# CC1312PSIP register map
File version: 1.0
CPU: CM4 1.0, other endian, MPU, FPU, 3 interrupt priority bits
Registers are 32-bit, read-write, reset 0x0 unless marked. A register's access mark holds for its fields unless they carry their own. Offsets are from the block's base; [hi:lo] are bit positions; {n}, {i} and the like mark numbered series.

## CCFG — Customer configuration area (CCFG)
Base 0x50003000
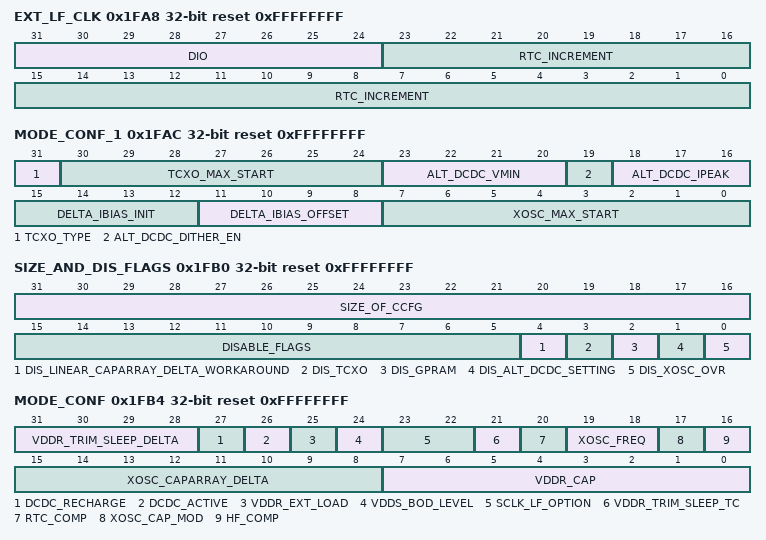
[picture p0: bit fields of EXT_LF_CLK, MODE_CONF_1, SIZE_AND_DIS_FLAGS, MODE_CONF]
0x1FA8 EXT_LF_CLK reset 0xFFFFFFFF — Extern LF clock configuration
  [31:24] DIO — [31:24] Unsigned integer, selecting the DIO to supply external 32 kHz clock as SCLK_LF when MODE_CONF.SCLK_LF_OPTION is set to EXTERNAL. The selected DIO will be marked as reserved by the pin driver (TI-RTOS environment) and hence not selectable for other usage.
  [23:0] RTC_INCREMENT — [23:0] Unsigned integer, defining the input frequency of the external clock and is written to AON_RTC:SUBSECINC.VALUEINC. Defined as follows: EXT_LF_CLK.RTC_INCREMENT = 2^38/InputClockFrequency in Hertz (e.g.: RTC_INCREMENT=0x800000 for InputClockFrequency=32768 Hz)
0x1FAC MODE_CONF_1 reset 0xFFFFFFFF — Mode Configuration 1
  [31] TCXO_TYPE — [31:31] Selects the TCXO type. 0: CMOS type. Internal common-mode bias will not be enabled. 1: Clipped-sine type. Internal common-mode bias will be enabled when TCXO is used. Bit field value is only valid if MODE_CONF.XOSC_FREQ=0.
  [30:24] TCXO_MAX_START — [30:24] Maximum TCXO startup time in units of 100us. Bit field value is only valid if MODE_CONF.XOSC_FREQ=0.
  [23:20] ALT_DCDC_VMIN — [23:20] Minimum voltage for when DC/DC should be used if alternate DC/DC setting is enabled (SIZE_AND_DIS_FLAGS.DIS_ALT_DCDC_SETTING=0). Voltage = (28 + ALT_DCDC_VMIN) / 16. 0: 1.75V 1: 1.8125V ... 14: 2.625V 15: 2.6875V NOTE! The DriverLib function SysCtrl_DCDC_VoltageConditionalControl() must be called regularly to apply this field (handled automatically if using TI RTOS!).
  [19] ALT_DCDC_DITHER_EN — [19:19] Enable DC/DC dithering if alternate DC/DC setting is enabled (SIZE_AND_DIS_FLAGS.DIS_ALT_DCDC_SETTING=0). 0: Dither disable 1: Dither enable
  [18:16] ALT_DCDC_IPEAK — [18:16] Inductor peak current if alternate DC/DC setting is enabled (SIZE_AND_DIS_FLAGS.DIS_ALT_DCDC_SETTING=0). Assuming 10uH external inductor! 0: 46mA (min) ... 4: 70mA ... 7: 87mA (max)
  [15:12] DELTA_IBIAS_INIT — [15:12] Signed delta value for IBIAS_INIT. Delta value only applies if SIZE_AND_DIS_FLAGS.DIS_XOSC_OVR=0. See FCFG1:AMPCOMP_CTRL1.IBIAS_INIT
  [11:8] DELTA_IBIAS_OFFSET — [11:8] Signed delta value for IBIAS_OFFSET. Delta value only applies if SIZE_AND_DIS_FLAGS.DIS_XOSC_OVR=0. See FCFG1:AMPCOMP_CTRL1.IBIAS_OFFSET
  [7:0] XOSC_MAX_START — [7:0] Unsigned value of maximum XOSC startup time (worst case) in units of 100us. Value only applies if SIZE_AND_DIS_FLAGS.DIS_XOSC_OVR=0.
0x1FB0 SIZE_AND_DIS_FLAGS reset 0xFFFFFFFF — CCFG Size and Disable Flags
  [31:16] SIZE_OF_CCFG — [31:16] Total size of CCFG in bytes.
  [15:5] DISABLE_FLAGS — [15:5] Reserved for future use. Software should not rely on the value of a reserved. Writing any other value than the reset/default value may result in undefined behavior.
  [4] DIS_LINEAR_CAPARRAY_DELTA_WORKAROUND — [4:4] The default CAPARRAY setting is good as long as no CAPARRAY_DELTA adjustment is added but the CAPARRAY setting will give an un-linear behavior if the workaround is not enabled. The workaround is disabled by default to avoid unexpected changes upon software updates. 0: The CAPARRAY_DELTA workaround is enabled. 1: The CAPARRAY_DELTA workaround is disabled.
  [3] DIS_TCXO — [3:3] Deprecated. Must be set to 1.
  [2] DIS_GPRAM — [2:2] Disable GPRAM (or use the 8K VIMS RAM as CACHE RAM). 0: GPRAM is enabled and hence CACHE disabled. 1: GPRAM is disabled and instead CACHE is enabled (default). Notes: - Disabling CACHE will reduce CPU execution speed (up to 60%). - GPRAM is 8 K-bytes in size and located at 0x11000000-0x11001FFF if enabled. See: VIMS:CTL.MODE
  [1] DIS_ALT_DCDC_SETTING — [1:1] Disable alternate DC/DC settings. 0: Enable alternate DC/DC settings. 1: Disable alternate DC/DC settings. See: MODE_CONF_1.ALT_DCDC_VMIN MODE_CONF_1.ALT_DCDC_DITHER_EN MODE_CONF_1.ALT_DCDC_IPEAK NOTE! The DriverLib function SysCtrl_DCDC_VoltageConditionalControl() must be called regularly to apply this field (handled automatically if using TI RTOS!).
  [0] DIS_XOSC_OVR — [0:0] Disable XOSC override functionality. 0: Enable XOSC override functionality. 1: Disable XOSC override functionality. See: MODE_CONF_1.DELTA_IBIAS_INIT MODE_CONF_1.DELTA_IBIAS_OFFSET MODE_CONF_1.XOSC_MAX_START
0x1FB4 MODE_CONF reset 0xFFFFFFFF — Mode Configuration 0
  [31:28] VDDR_TRIM_SLEEP_DELTA — [31:28] Signed delta value to apply to the VDDR_TRIM_SLEEP target, minus one. See FCFG1:VOLT_TRIM.VDDR_TRIM_SLEEP_H. 0x8 (-8) : Delta = -7 ... 0xF (-1) : Delta = 0 0x0 (0) : Delta = +1 ... 0x7 (7) : Delta = +8
  [27] DCDC_RECHARGE — [27:27] DC/DC during recharge in powerdown. 0: Use the DC/DC during recharge in powerdown. 1: Do not use the DC/DC during recharge in powerdown (default). NOTE! The DriverLib function SysCtrl_DCDC_VoltageConditionalControl() must be called regularly to apply this field (handled automatically if using TI RTOS!).
  [26] DCDC_ACTIVE — [26:26] DC/DC in active mode. 0: Use the DC/DC during active mode. 1: Do not use the DC/DC during active mode (default). NOTE! The DriverLib function SysCtrl_DCDC_VoltageConditionalControl() must be called regularly to apply this field (handled automatically if using TI RTOS!).
  [25] VDDR_EXT_LOAD — [25:25] Reserved for future use. Software should not rely on the value of a reserved. Writing any other value than the reset/default value may result in undefined behavior.
  [24] VDDS_BOD_LEVEL — [24:24] VDDS BOD level. 0: VDDS BOD level is 2.0V (necessary for external load mode, or for maximum PA output power on CC13xx). 1: VDDS BOD level is 1.8V (or 1.65V for external regulator mode) (default).
  [23:22] SCLK_LF_OPTION — [23:22] Select source for SCLK_LF.
    3=RCOSC_LF (Low frequency RCOSC (default)); 2=XOSC_LF (32.768 kHz low frequency XOSC); 1=EXTERNAL_LF (External low frequency clock on DIO defined by EXT_LF_CLK.DIO. The RTC tick speed AON_RTC:SUBSECINC is updated to EXT_LF_CLK.RTC_INCREMENT (done in the SetupTrimDevice() driverlib boot function). External clock must always be running when the chip is in standby for VDDR recharge timing.); 0=XOSC_HF_DLF (31.25 kHz clock derived from 48 MHz XOSC or HPOSC. The RTC tick speed AON_RTC:SUBSECINC is updated to 0x8637BD, corresponding to a 31.25 kHz clock (done in the SetupTrimDevice() driverlib boot function). The device must be blocked from entering Standby mode when using this clock source.)
  [21] VDDR_TRIM_SLEEP_TC — [21:21] 0x1: VDDR_TRIM_SLEEP_DELTA is not temperature compensated 0x0: RTOS/driver temperature compensates VDDR_TRIM_SLEEP_DELTA every time standby mode is entered. This improves low-temperature RCOSC_LF frequency stability in standby mode. When temperature compensation is performed, the delta is calculates this way: Delta = max (delta, min(8, floor(62-temp)/8)) Here, delta is given by VDDR_TRIM_SLEEP_DELTA, and temp is the current temperature in degrees C.
  [20] RTC_COMP — [20:20] Reserved for future use. Software should not rely on the value of a reserved. Writing any other value than the reset/default value may result in undefined behavior.
  [19:18] XOSC_FREQ — [19:18] Selects which high frequency oscillator is used (required for radio usage).
    3=24M (24 MHz XOSC_HF. Not supported.); 2=48M (48 MHz XOSC_HF); 1=HPOSC (Internal high precision oscillator.); 0=TCXO (External 48 MHz TCXO. Refer to MODE_CONF_1.TCXO_MAX_START and MODE_CONF_1.TCXO_TYPE bit fields for additional configuration of TCXO.)
  [17] XOSC_CAP_MOD — [17:17] Enable modification (delta) to XOSC cap-array. Value specified in XOSC_CAPARRAY_DELTA. 0: Apply cap-array delta 1: Do not apply cap-array delta (default)
  [16] HF_COMP — [16:16] Reserved for future use. Software should not rely on the value of a reserved. Writing any other value than the reset/default value may result in undefined behavior.
  [15:8] XOSC_CAPARRAY_DELTA — [15:8] Signed 8-bit value, directly modifying trimmed XOSC cap-array step value. Enabled by XOSC_CAP_MOD.
  [7:0] VDDR_CAP — [7:0] Unsigned 8-bit integer, representing the minimum decoupling capacitance (worst case) on VDDR, in units of 100nF. This should take into account capacitor tolerance and voltage dependent capacitance variation. This bit affects the recharge period calculation when going into powerdown or standby. NOTE! If using the following functions this field must be configured (used by TI RTOS): SysCtrlSetRechargeBeforePowerDown() SysCtrlAdjustRechargeAfterPowerDown()
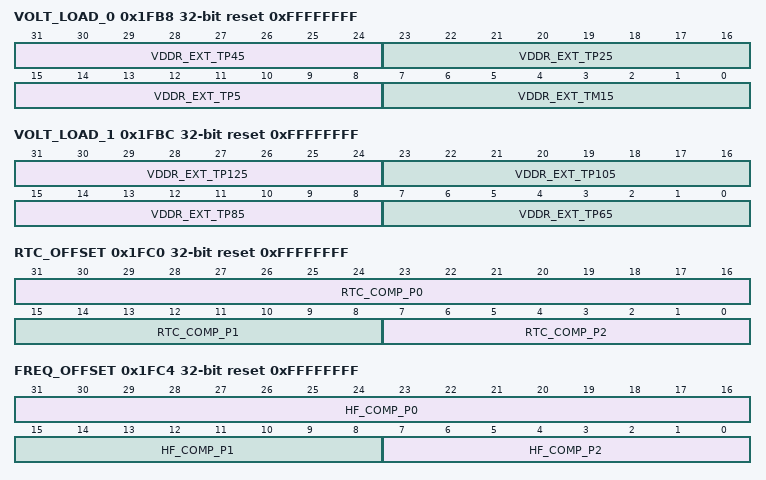
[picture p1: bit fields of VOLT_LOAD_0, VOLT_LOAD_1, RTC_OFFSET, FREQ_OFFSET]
0x1FB8 VOLT_LOAD_0 reset 0xFFFFFFFF — Voltage Load 0 Enabled by MODE_CONF.VDDR_EXT_LOAD.
  [31:24] VDDR_EXT_TP45 — [31:24] Reserved for future use. Software should not rely on the value of a reserved. Writing any other value than the reset/default value may result in undefined behavior.
  [23:16] VDDR_EXT_TP25 — [23:16] Reserved for future use. Software should not rely on the value of a reserved. Writing any other value than the reset/default value may result in undefined behavior.
  [15:8] VDDR_EXT_TP5 — [15:8] Reserved for future use. Software should not rely on the value of a reserved. Writing any other value than the reset/default value may result in undefined behavior.
  [7:0] VDDR_EXT_TM15 — [7:0] Reserved for future use. Software should not rely on the value of a reserved. Writing any other value than the reset/default value may result in undefined behavior.
0x1FBC VOLT_LOAD_1 reset 0xFFFFFFFF — Voltage Load 1 Enabled by MODE_CONF.VDDR_EXT_LOAD.
  [31:24] VDDR_EXT_TP125 — [31:24] Reserved for future use. Software should not rely on the value of a reserved. Writing any other value than the reset/default value may result in undefined behavior.
  [23:16] VDDR_EXT_TP105 — [23:16] Reserved for future use. Software should not rely on the value of a reserved. Writing any other value than the reset/default value may result in undefined behavior.
  [15:8] VDDR_EXT_TP85 — [15:8] Reserved for future use. Software should not rely on the value of a reserved. Writing any other value than the reset/default value may result in undefined behavior.
  [7:0] VDDR_EXT_TP65 — [7:0] Reserved for future use. Software should not rely on the value of a reserved. Writing any other value than the reset/default value may result in undefined behavior.
0x1FC0 RTC_OFFSET reset 0xFFFFFFFF — Real Time Clock Offset Enabled by MODE_CONF.RTC_COMP.
  [31:16] RTC_COMP_P0 — [31:16] Reserved for future use. Software should not rely on the value of a reserved. Writing any other value than the reset/default value may result in undefined behavior.
  [15:8] RTC_COMP_P1 — [15:8] Reserved for future use. Software should not rely on the value of a reserved. Writing any other value than the reset/default value may result in undefined behavior.
  [7:0] RTC_COMP_P2 — [7:0] Reserved for future use. Software should not rely on the value of a reserved. Writing any other value than the reset/default value may result in undefined behavior.
0x1FC4 FREQ_OFFSET reset 0xFFFFFFFF — Frequency Offset
  [31:16] HF_COMP_P0 — [31:16] Reserved for future use. Software should not rely on the value of a reserved. Writing any other value than the reset/default value may result in undefined behavior.
  [15:8] HF_COMP_P1 — [15:8] Reserved for future use. Software should not rely on the value of a reserved. Writing any other value than the reset/default value may result in undefined behavior.
  [7:0] HF_COMP_P2 — [7:0] Reserved for future use. Software should not rely on the value of a reserved. Writing any other value than the reset/default value may result in undefined behavior.
0x1FC8 IEEE_MAC_0 reset 0xFFFFFFFF — IEEE MAC Address 0
  [31:0] ADDR — [31:0] Bits[31:0] of the 64-bits custom IEEE MAC address. If different from 0xFFFFFFFF then the value of this field is applied; otherwise use value from FCFG.
0x1FCC IEEE_MAC_1 reset 0xFFFFFFFF — IEEE MAC Address 1
  [31:0] ADDR — [31:0] Bits[63:32] of the 64-bits custom IEEE MAC address. If different from 0xFFFFFFFF then the value of this field is applied; otherwise use value from FCFG.
0x1FD0 IEEE_BLE_0 reset 0xFFFFFFFF — IEEE BLE Address 0
  [31:0] ADDR — [31:0] Bits[31:0] of the 64-bits custom IEEE BLE address. If different from 0xFFFFFFFF then the value of this field is applied; otherwise use value from FCFG.
0x1FD4 IEEE_BLE_1 reset 0xFFFFFFFF — IEEE BLE Address 1
  [31:0] ADDR — [31:0] Bits[63:32] of the 64-bits custom IEEE BLE address. If different from 0xFFFFFFFF then the value of this field is applied; otherwise use value from FCFG.
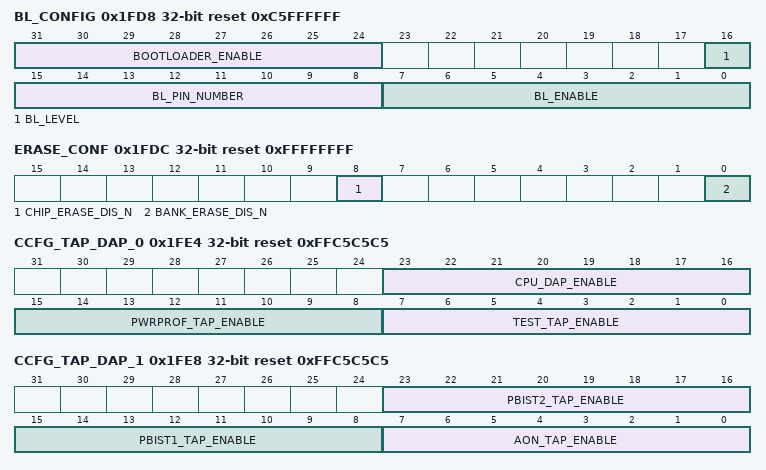
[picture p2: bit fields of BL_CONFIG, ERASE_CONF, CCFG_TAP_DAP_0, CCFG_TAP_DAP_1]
0x1FD8 BL_CONFIG reset 0xC5FFFFFF — Bootloader Configuration Configures the functionality of the ROM boot loader. If both the boot loader is enabled by the BOOTLOADER_ENABLE field and the boot loader backdoor is enabled by the BL_ENABLE field it is possible to force entry of the ROM boot loader even if a valid image is present in flash.
  [31:24] BOOTLOADER_ENABLE — [31:24] Bootloader enable. Boot loader can be accessed if IMAGE_VALID_CONF.IMAGE_VALID is non-zero or BL_ENABLE is enabled (and conditions for boot loader backdoor are met). 0xC5: Boot loader is enabled. Any other value: Boot loader is disabled.
  [16] BL_LEVEL — [16:16] Sets the active level of the selected DIO number BL_PIN_NUMBER if boot loader backdoor is enabled by the BL_ENABLE field. 0: Active low. 1: Active high.
  [15:8] BL_PIN_NUMBER — [15:8] DIO number that is level checked if the boot loader backdoor is enabled by the BL_ENABLE field.
  [7:0] BL_ENABLE — [7:0] Enables the boot loader backdoor. 0xC5: Boot loader backdoor is enabled. Any other value: Boot loader backdoor is disabled. NOTE! Boot loader must be enabled (see BOOTLOADER_ENABLE) if boot loader backdoor is enabled.
0x1FDC ERASE_CONF reset 0xFFFFFFFF — Erase Configuration
  [8] CHIP_ERASE_DIS_N — [8:8] Chip erase. This bit controls if a chip erase requested through the JTAG WUC TAP will be ignored in a following boot caused by a reset of the MCU VD. A successful chip erase operation will force the content of the flash main bank back to the state as it was when delivered by TI. 0: Disable. Any chip erase request detected during boot will be ignored. 1: Enable. Any chip erase request detected during boot will be performed by the boot FW.
  [0] BANK_ERASE_DIS_N — [0:0] Bank erase. This bit controls if the ROM serial boot loader will accept a received Bank Erase command (COMMAND_BANK_ERASE). A successful Bank Erase operation will erase all main bank sectors not protected by write protect configuration bits in CCFG. 0: Disable the boot loader bank erase function. 1: Enable the boot loader bank erase function.
0x1FE0 CCFG_TI_OPTIONS reset 0xFFFFFFC5 — TI Options
  [7:0] TI_FA_ENABLE — [7:0] TI Failure Analysis. 0xC5: Enable the functionality of unlocking the TI FA (TI Failure Analysis) option with the unlock code. All other values: Disable the functionality of unlocking the TI FA option with the unlock code.
0x1FE4 CCFG_TAP_DAP_0 reset 0xFFC5C5C5 — Test Access Points Enable 0
  [23:16] CPU_DAP_ENABLE — [23:16] Enable CPU DAP. 0xC5: Main CPU DAP access is enabled during power-up/system-reset by ROM boot FW. Any other value: Main CPU DAP access will remain disabled out of power-up/system-reset.
  [15:8] PWRPROF_TAP_ENABLE — [15:8] Enable PWRPROF TAP. 0xC5: PWRPROF TAP access is enabled during power-up/system-reset by ROM boot FW if enabled by corresponding configuration value in FCFG1 defined by TI. Any other value: PWRPROF TAP access will remain disabled out of power-up/system-reset.
  [7:0] TEST_TAP_ENABLE — [7:0] Enable Test TAP. 0xC5: TEST TAP access is enabled during power-up/system-reset by ROM boot FW if enabled by corresponding configuration value in FCFG1 defined by TI. Any other value: TEST TAP access will remain disabled out of power-up/system-reset.
0x1FE8 CCFG_TAP_DAP_1 reset 0xFFC5C5C5 — Test Access Points Enable 1
  [23:16] PBIST2_TAP_ENABLE — [23:16] Enable PBIST2 TAP. 0xC5: PBIST2 TAP access is enabled during power-up/system-reset by ROM boot FW if enabled by corresponding configuration value in FCFG1 defined by TI. Any other value: PBIST2 TAP access will remain disabled out of power-up/system-reset.
  [15:8] PBIST1_TAP_ENABLE — [15:8] Enable PBIST1 TAP. 0xC5: PBIST1 TAP access is enabled during power-up/system-reset by ROM boot FW if enabled by corresponding configuration value in FCFG1 defined by TI. Any other value: PBIST1 TAP access will remain disabled out of power-up/system-reset.
  [7:0] AON_TAP_ENABLE — [7:0] Enable AON TAP 0xC5: AON TAP access is enabled during power-up/system-reset by ROM boot FW if enabled by corresponding configuration value in FCFG1 defined by TI. Any other value: AON TAP access will remain disabled out of power-up/system-reset.
0x1FEC IMAGE_VALID_CONF reset 0xFFFFFFFF — Image Valid
  [31:0] IMAGE_VALID — [31:0] This field must have the address value of the start of the flash vector table in order to enable the boot FW in ROM to transfer control to a flash image. Any illegal vector table start address value will force the boot FW in ROM to transfer control to the serial boot loader in ROM.
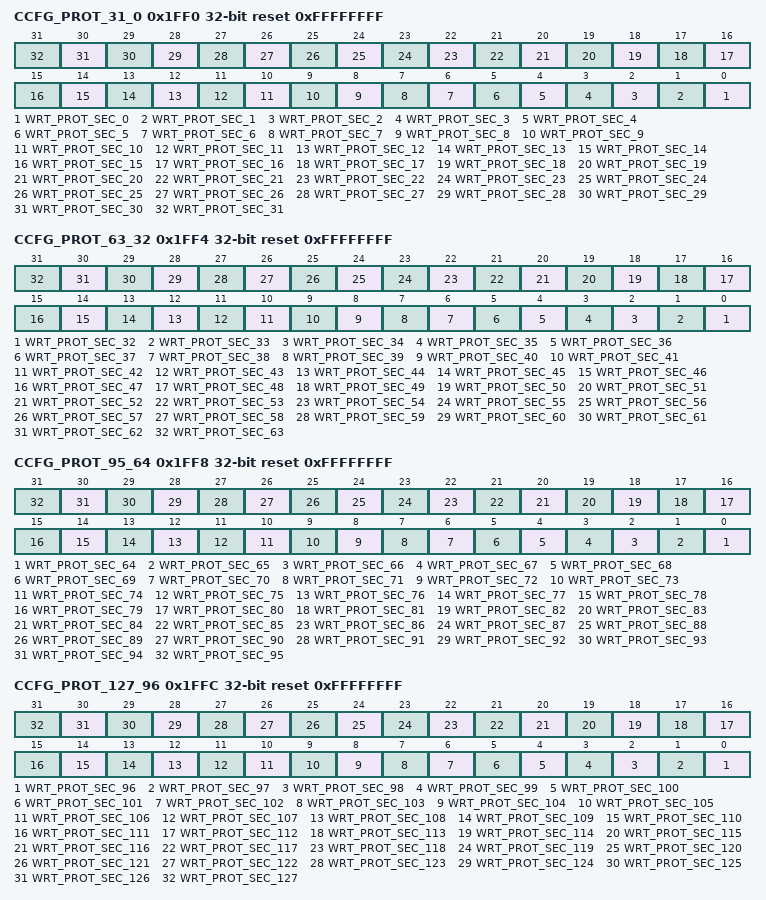
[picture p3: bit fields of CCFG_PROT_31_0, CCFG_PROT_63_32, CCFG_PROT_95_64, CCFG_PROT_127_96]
0x1FF0 CCFG_PROT_31_0 reset 0xFFFFFFFF — Protect Sectors 0-31 Each bit write protects one 8KB flash sector from being both programmed and erased. Bit must be set to 0 in order to enable sector write protect.
  [n] WRT_PROT_SEC_{n} (n=0..31) — [{n}:{n}] 0: Sector protected
0x1FF4 CCFG_PROT_63_32 reset 0xFFFFFFFF — Protect Sectors 32-63 Each bit write protects one 8KB flash sector from being both programmed and erased. Bit must be set to 0 in order to enable sector write protect.
  [n-32] WRT_PROT_SEC_{n} (n=32..63) — [{n-32}:{n-32}] 0: Sector protected
0x1FF8 CCFG_PROT_95_64 reset 0xFFFFFFFF — Protect Sectors 64-95 Each bit write protects one flash sector from being both programmed and erased. Bit must be set to 0 in order to enable sector write protect. Not in use.
  [n-64] WRT_PROT_SEC_{n} (n=64..95) — [{n-64}:{n-64}] 0: Sector protected
0x1FFC CCFG_PROT_127_96 reset 0xFFFFFFFF — Protect Sectors 96-127 Each bit write protects one flash sector from being both programmed and erased. Bit must be set to 0 in order to enable sector write protect. Not in use.
  [n-96] WRT_PROT_SEC_{n} (n=96..127) — [{n-96}:{n-96}] 0: Sector protected
